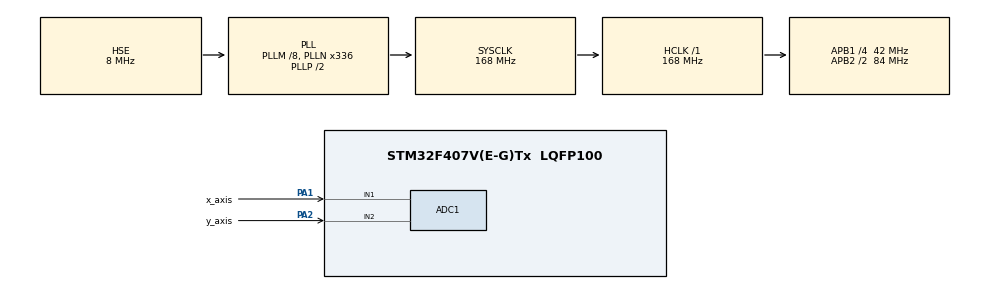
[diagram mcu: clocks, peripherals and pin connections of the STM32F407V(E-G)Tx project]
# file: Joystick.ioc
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ADC1.Channel-0\#ChannelRegularConversion=ADC_CHANNEL_1
ADC1.Channel-1\#ChannelRegularConversion=ADC_CHANNEL_2
ADC1.ContinuousConvMode=ENABLE
ADC1.DMAContinuousRequests=ENABLE
ADC1.NbrOfConversion=2
ADC1.NbrOfConversionFlag=1
ADC1.Rank-0\#ChannelRegularConversion=1
ADC1.Rank-1\#ChannelRegularConversion=2
ADC1.SamplingTime-0\#ChannelRegularConversion=ADC_SAMPLETIME_56CYCLES
ADC1.SamplingTime-1\#ChannelRegularConversion=ADC_SAMPLETIME_56CYCLES
ADC1.ScanConvMode=ENABLE
ADC1.master=1
Dma.ADC1.0.Direction=DMA_PERIPH_TO_MEMORY
Dma.ADC1.0.FIFOMode=DMA_FIFOMODE_DISABLE
Dma.ADC1.0.Instance=DMA2_Stream0
Dma.ADC1.0.MemDataAlignment=DMA_MDATAALIGN_WORD
Dma.ADC1.0.MemInc=DMA_MINC_ENABLE
Dma.ADC1.0.Mode=DMA_CIRCULAR
Dma.ADC1.0.PeriphDataAlignment=DMA_PDATAALIGN_WORD
Dma.ADC1.0.PeriphInc=DMA_PINC_DISABLE
Dma.ADC1.0.Priority=DMA_PRIORITY_LOW
Dma.Request0=ADC1
Mcu.Family=STM32F4
Mcu.Name=STM32F407V(E-G)Tx
Mcu.Package=LQFP100
NVIC.DMA2_Stream0_IRQn=true\:0\:0\:false\:false\:true\:false\:true\:true
NVIC.PriorityGroup=NVIC_PRIORITYGROUP_0
PA1.GPIO_Label=x_axis
PA1.Signal=ADCx_IN1
PA13.Mode=Serial_Wire
PA13.Signal=SYS_JTMS-SWDIO
PA14.Mode=Serial_Wire
PA14.Signal=SYS_JTCK-SWCLK
PA2.GPIO_Label=y_axis
PA2.Signal=ADCx_IN2
PH0-OSC_IN.Mode=HSE-External-Oscillator
PH0-OSC_IN.Signal=RCC_OSC_IN
PH1-OSC_OUT.Mode=HSE-External-Oscillator
PH1-OSC_OUT.Signal=RCC_OSC_OUT
ProjectManager.HeapSize=0x200
ProjectManager.StackSize=0x400
ProjectManager.TargetToolchain=STM32CubeIDE
RCC.48MHZClocksFreq_Value=48000000
RCC.AHBFreq_Value=168000000
RCC.APB1CLKDivider=RCC_HCLK_DIV4
RCC.APB1Freq_Value=42000000
RCC.APB1TimFreq_Value=84000000
RCC.APB2CLKDivider=RCC_HCLK_DIV2
RCC.APB2Freq_Value=84000000
RCC.APB2TimFreq_Value=168000000
RCC.CortexFreq_Value=168000000
RCC.HCLKFreq_Value=168000000
RCC.HSE_VALUE=8000000
RCC.HSI_VALUE=16000000
RCC.LSE_VALUE=32768
RCC.PLLM=8
RCC.PLLN=336
RCC.PLLQ=7
RCC.PLLSourceVirtual=RCC_PLLSOURCE_HSE
RCC.SYSCLKFreq_VALUE=168000000
RCC.SYSCLKSource=RCC_SYSCLKSOURCE_PLLCLK
RCC.VCOOutputFreq_Value=336000000
SH.ADCx_IN1.0=ADC1_IN1,IN1
SH.ADCx_IN2.0=ADC1_IN2,IN2
board=STM32F407G-DISC1

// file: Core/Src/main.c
/* USER CODE BEGIN Header */
/**
  ******************************************************************************
  * @file           : main.c
  * @brief          : Main program body
  ******************************************************************************
  * @attention
  *
  * <h2><center>&copy; Copyright (c) 2021 STMicroelectronics.
  * All rights reserved.</center></h2>
  *
  * This software component is licensed by ST under Ultimate Liberty license
  * SLA0044, the "License"; You may not use this file except in compliance with
  * the License. You may obtain a copy of the License at:
  *                             www.st.com/SLA0044
  *
  ******************************************************************************
  */
/* USER CODE END Header */
#include "main.h"

ADC_HandleTypeDef hadc1;
DMA_HandleTypeDef hdma_adc1;

/* USER CODE BEGIN PV */
uint32_t adcData[2]={0};
uint32_t x_axisData=0;
uint32_t y_axisData=0;
float mapDataX=0;
float mapDataY=0;

/* USER CODE END PV */

void SystemClock_Config(void);
static void MX_GPIO_Init(void);
static void MX_DMA_Init(void);
static void MX_ADC1_Init(void);

/* USER CODE BEGIN 0 */

float map(float adcValue, float max, float min, float conMax, float conMin){

   return (adcValue*((conMax-conMin)/(max-min)))-100;
}

/* USER CODE END 0 */

int main(void)
{

  /* MCU Configuration--------------------------------------------------------*/

  /* Reset of all peripherals, Initializes the Flash interface and the Systick. */
  HAL_Init();

  /* Configure the system clock */
  SystemClock_Config();

  /* Initialize all configured peripherals */
  MX_GPIO_Init();
  MX_DMA_Init();
  MX_ADC1_Init();
  /* USER CODE BEGIN 2 */

  HAL_ADC_Start_DMA(&hadc1, adcData, sizeof(adcData));
  /* USER CODE END 2 */

  /* Infinite loop */
  while (1)
  {

    /* USER CODE BEGIN 3 */
	  mapDataX=map(x_axisData, 0, 4095, -100, 100);
	  mapDataY=map(y_axisData, 0, 4095, -100, 100);

  }
  /* USER CODE END 3 */
}

void SystemClock_Config(void)
{
  RCC_OscInitTypeDef RCC_OscInitStruct = {0};
  RCC_ClkInitTypeDef RCC_ClkInitStruct = {0};

  /** Configure the main internal regulator output voltage
  */
  __HAL_RCC_PWR_CLK_ENABLE();
  __HAL_PWR_VOLTAGESCALING_CONFIG(PWR_REGULATOR_VOLTAGE_SCALE1);

  /** Initializes the RCC Oscillators according to the specified parameters
  * in the RCC_OscInitTypeDef structure.
  */
  RCC_OscInitStruct.OscillatorType = RCC_OSCILLATORTYPE_HSE;
  RCC_OscInitStruct.HSEState = RCC_HSE_ON;
  RCC_OscInitStruct.PLL.PLLState = RCC_PLL_ON;
  RCC_OscInitStruct.PLL.PLLSource = RCC_PLLSOURCE_HSE;
  RCC_OscInitStruct.PLL.PLLM = 8;
  RCC_OscInitStruct.PLL.PLLN = 336;
  RCC_OscInitStruct.PLL.PLLP = RCC_PLLP_DIV2;
  RCC_OscInitStruct.PLL.PLLQ = 7;
  if (HAL_RCC_OscConfig(&RCC_OscInitStruct) != HAL_OK)
  {
    Error_Handler();
  }

  /** Initializes the CPU, AHB and APB buses clocks
  */
  RCC_ClkInitStruct.ClockType = RCC_CLOCKTYPE_HCLK|RCC_CLOCKTYPE_SYSCLK
                              |RCC_CLOCKTYPE_PCLK1|RCC_CLOCKTYPE_PCLK2;
  RCC_ClkInitStruct.SYSCLKSource = RCC_SYSCLKSOURCE_PLLCLK;
  RCC_ClkInitStruct.AHBCLKDivider = RCC_SYSCLK_DIV1;
  RCC_ClkInitStruct.APB1CLKDivider = RCC_HCLK_DIV4;
  RCC_ClkInitStruct.APB2CLKDivider = RCC_HCLK_DIV2;

  if (HAL_RCC_ClockConfig(&RCC_ClkInitStruct, FLASH_LATENCY_5) != HAL_OK)
  {
    Error_Handler();
  }
}

static void MX_ADC1_Init(void)
{

  ADC_ChannelConfTypeDef sConfig = {0};

  /** Configure the global features of the ADC (Clock, Resolution, Data Alignment and number of conversion)
  */
  hadc1.Instance = ADC1;
  hadc1.Init.ClockPrescaler = ADC_CLOCK_SYNC_PCLK_DIV4;
  hadc1.Init.Resolution = ADC_RESOLUTION_12B;
  hadc1.Init.ScanConvMode = ENABLE;
  hadc1.Init.ContinuousConvMode = ENABLE;
  hadc1.Init.DiscontinuousConvMode = DISABLE;
  hadc1.Init.ExternalTrigConvEdge = ADC_EXTERNALTRIGCONVEDGE_NONE;
  hadc1.Init.ExternalTrigConv = ADC_SOFTWARE_START;
  hadc1.Init.DataAlign = ADC_DATAALIGN_RIGHT;
  hadc1.Init.NbrOfConversion = 2;
  hadc1.Init.DMAContinuousRequests = ENABLE;
  hadc1.Init.EOCSelection = ADC_EOC_SINGLE_CONV;
  if (HAL_ADC_Init(&hadc1) != HAL_OK)
  {
    Error_Handler();
  }

  /** Configure for the selected ADC regular channel its corresponding rank in the sequencer and its sample time.
  */
  sConfig.Channel = ADC_CHANNEL_1;
  sConfig.Rank = 1;
  sConfig.SamplingTime = ADC_SAMPLETIME_56CYCLES;
  if (HAL_ADC_ConfigChannel(&hadc1, &sConfig) != HAL_OK)
  {
    Error_Handler();
  }

  /** Configure for the selected ADC regular channel its corresponding rank in the sequencer and its sample time.
  */
  sConfig.Channel = ADC_CHANNEL_2;
  sConfig.Rank = 2;
  if (HAL_ADC_ConfigChannel(&hadc1, &sConfig) != HAL_OK)
  {
    Error_Handler();
  }

}

static void MX_DMA_Init(void)
{

  /* DMA controller clock enable */
  __HAL_RCC_DMA2_CLK_ENABLE();

  /* DMA interrupt init */
  /* DMA2_Stream0_IRQn interrupt configuration */
  HAL_NVIC_SetPriority(DMA2_Stream0_IRQn, 0, 0);
  HAL_NVIC_EnableIRQ(DMA2_Stream0_IRQn);

}

static void MX_GPIO_Init(void)
{

  /* GPIO Ports Clock Enable */
  __HAL_RCC_GPIOH_CLK_ENABLE();
  __HAL_RCC_GPIOA_CLK_ENABLE();

}

/* USER CODE BEGIN 4 */
void HAL_ADC_ConvCpltCallback(ADC_HandleTypeDef* hadc)
{

	if(hadc->Instance==&hadc1){
		adcData[0]=x_axisData;
		adcData[1]=y_axisData;

	}
}

/* USER CODE END 4 */

void Error_Handler(void)
{
  __disable_irq();
  while (1)
  {
  }
}
